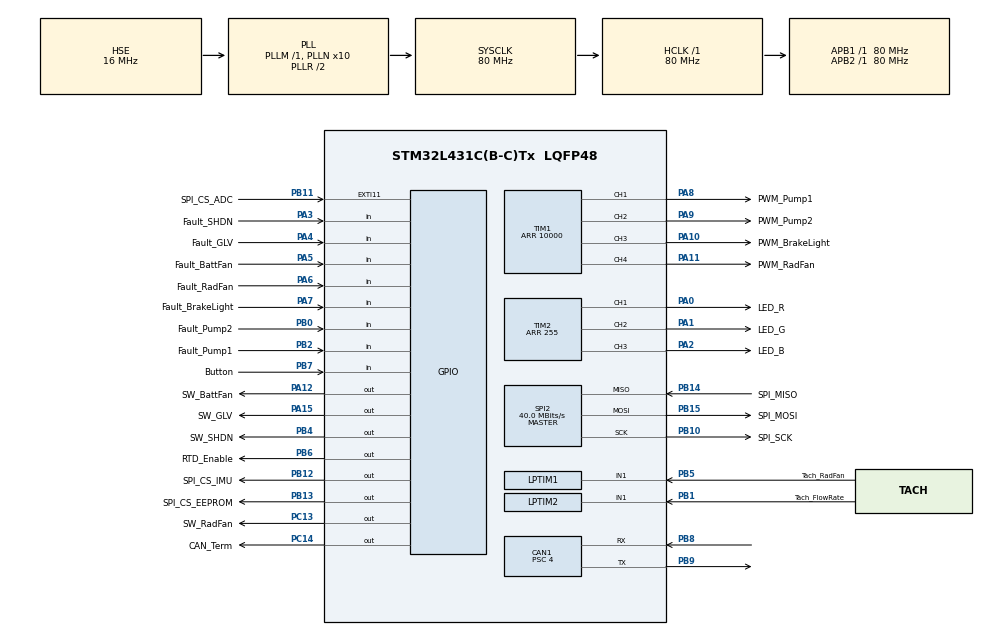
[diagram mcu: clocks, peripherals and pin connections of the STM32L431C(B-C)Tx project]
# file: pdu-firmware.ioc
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CAN1.BS1=CAN_BS1_16TQ
CAN1.BS2=CAN_BS2_3TQ
CAN1.CalculateBaudRate=1000000
CAN1.CalculateTimeBit=1000
CAN1.CalculateTimeQuantum=50.0
CAN1.Prescaler=4
Mcu.Family=STM32L4
Mcu.Name=STM32L431C(B-C)Tx
Mcu.Package=LQFP48
NVIC.PriorityGroup=NVIC_PRIORITYGROUP_4
PA0.GPIO_Label=LED_R
PA0.GPIO_ModeDefaultPP=GPIO_MODE_AF_OD
PA0.GPIO_Speed=GPIO_SPEED_FREQ_VERY_HIGH
PA0.Signal=S_TIM2_CH1
PA1.GPIO_Label=LED_G
PA1.GPIO_ModeDefaultPP=GPIO_MODE_AF_OD
PA1.GPIO_Speed=GPIO_SPEED_FREQ_VERY_HIGH
PA1.Signal=S_TIM2_CH2
PA10.GPIO_Label=PWM_BrakeLight
PA10.Signal=S_TIM1_CH3
PA11.GPIO_Label=PWM_RadFan
PA11.Signal=S_TIM1_CH4
PA12.GPIO_Label=SW_BattFan
PA12.Signal=GPIO_Output
PA13\ (JTMS-SWDIO).Mode=Trace_Asynchronous_SW
PA13\ (JTMS-SWDIO).Signal=SYS_JTMS-SWDIO
PA14\ (JTCK-SWCLK).Mode=Trace_Asynchronous_SW
PA14\ (JTCK-SWCLK).Signal=SYS_JTCK-SWCLK
PA15\ (JTDI).GPIO_Label=SW_GLV
PA15\ (JTDI).Signal=GPIO_Output
PA2.GPIO_Label=LED_B
PA2.GPIO_ModeDefaultPP=GPIO_MODE_AF_OD
PA2.GPIO_Speed=GPIO_SPEED_FREQ_VERY_HIGH
PA2.Signal=S_TIM2_CH3
PA3.GPIO_Label=Fault_SHDN
PA3.Signal=GPIO_Input
PA4.GPIO_Label=Fault_GLV
PA4.Signal=GPIO_Input
PA5.GPIO_Label=Fault_BattFan
PA5.Signal=GPIO_Input
PA6.GPIO_Label=Fault_RadFan
PA6.Signal=GPIO_Input
PA7.GPIO_Label=Fault_BrakeLight
PA7.Signal=GPIO_Input
PA8.GPIO_Label=PWM_Pump1
PA8.Signal=S_TIM1_CH1
PA9.GPIO_Label=PWM_Pump2
PA9.Signal=S_TIM1_CH2
PB0.GPIO_Label=Fault_Pump2
PB0.Signal=GPIO_Input
PB1.GPIO_Label=Tach_FlowRate
PB1.Mode=Counts_external_clock_standalone_1X_occur1
PB1.Signal=LPTIM2_IN1
PB10.GPIO_Label=SPI_SCK
PB10.Mode=Full_Duplex_Master
PB10.Signal=SPI2_SCK
PB11.GPIO_Label=SPI_CS_ADC
PB11.Signal=GPXTI11
PB12.GPIO_Label=SPI_CS_IMU
PB12.Signal=GPIO_Output
PB13.GPIO_Label=SPI_CS_EEPROM
PB13.Signal=GPIO_Output
PB14.GPIO_Label=SPI_MISO
PB14.Mode=Full_Duplex_Master
PB14.Signal=SPI2_MISO
PB15.GPIO_Label=SPI_MOSI
PB15.Mode=Full_Duplex_Master
PB15.Signal=SPI2_MOSI
PB2.GPIO_Label=Fault_Pump1
PB2.Signal=GPIO_Input
PB3\ (JTDO-TRACESWO).Mode=Trace_Asynchronous_SW
PB3\ (JTDO-TRACESWO).Signal=SYS_JTDO-SWO
PB4\ (NJTRST).GPIO_Label=SW_SHDN
PB4\ (NJTRST).Signal=GPIO_Output
PB5.GPIO_Label=Tach_RadFan
PB5.Mode=Counts_external_clock_standalone_1X_occur1
PB5.Signal=LPTIM1_IN1
PB6.GPIO_Label=RTD_Enable
PB6.Signal=GPIO_Output
PB7.GPIO_Label=Button
PB7.Signal=GPIO_Input
PB8.Mode=CAN_Activate
PB8.Signal=CAN1_RX
PB9.Mode=CAN_Activate
PB9.Signal=CAN1_TX
PC13.GPIO_Label=SW_RadFan
PC13.Signal=GPIO_Output
PC14-OSC32_IN\ (PC14).GPIO_Label=CAN_Term
PC14-OSC32_IN\ (PC14).Signal=GPIO_Output
PH0-OSC_IN\ (PH0).Mode=HSE-External-Oscillator
PH0-OSC_IN\ (PH0).Signal=RCC_OSC_IN
PH1-OSC_OUT\ (PH1).Mode=HSE-External-Oscillator
PH1-OSC_OUT\ (PH1).Signal=RCC_OSC_OUT
ProjectManager.HeapSize=0x200
ProjectManager.StackSize=0x400
ProjectManager.TargetToolchain=STM32CubeIDE
RCC.ADCFreq_Value=64000000
RCC.AHBFreq_Value=80000000
RCC.APB1Freq_Value=80000000
RCC.APB1TimFreq_Value=80000000
RCC.APB2Freq_Value=80000000
RCC.APB2TimFreq_Value=80000000
RCC.CortexFreq_Value=80000000
RCC.HCLKFreq_Value=80000000
RCC.HSE_VALUE=16000000
RCC.HSI48_VALUE=48000000
RCC.HSI_VALUE=16000000
RCC.LSE_VALUE=32768
RCC.MSI_VALUE=4000000
RCC.PLLN=10
RCC.PLLSourceVirtual=RCC_PLLSOURCE_HSE
RCC.SYSCLKFreq_VALUE=80000000
RCC.SYSCLKSource=RCC_SYSCLKSOURCE_PLLCLK
RCC.VCOOutputFreq_Value=160000000
SH.S_TIM1_CH1.0=TIM1_CH1,PWM Generation1 CH1
SH.S_TIM1_CH2.0=TIM1_CH2,PWM Generation2 CH2
SH.S_TIM1_CH3.0=TIM1_CH3,PWM Generation3 CH3
SH.S_TIM1_CH4.0=TIM1_CH4,PWM Generation4 CH4
SH.S_TIM2_CH1.0=TIM2_CH1,PWM Generation1 CH1
SH.S_TIM2_CH2.0=TIM2_CH2,PWM Generation2 CH2
SH.S_TIM2_CH3.0=TIM2_CH3,PWM Generation3 CH3
SPI2.CalculateBaudRate=40.0 MBits/s
SPI2.Direction=SPI_DIRECTION_2LINES
SPI2.Mode=SPI_MODE_MASTER
SPI2.VirtualType=VM_MASTER
TIM1.Channel-PWM\ Generation1\ CH1=TIM_CHANNEL_1
TIM1.Channel-PWM\ Generation2\ CH2=TIM_CHANNEL_2
TIM1.Channel-PWM\ Generation3\ CH3=TIM_CHANNEL_3
TIM1.Channel-PWM\ Generation4\ CH4=TIM_CHANNEL_4
TIM1.Period=10000
TIM2.AutoReloadPreload=TIM_AUTORELOAD_PRELOAD_ENABLE
TIM2.Channel-PWM\ Generation1\ CH1=TIM_CHANNEL_1
TIM2.Channel-PWM\ Generation2\ CH2=TIM_CHANNEL_2
TIM2.Channel-PWM\ Generation3\ CH3=TIM_CHANNEL_3
TIM2.OCPolarity_1=TIM_OCPOLARITY_LOW
TIM2.OCPolarity_2=TIM_OCPOLARITY_LOW
TIM2.OCPolarity_3=TIM_OCPOLARITY_LOW
TIM2.Period=255
VP_TIM1_VS_ClockSourceINT.Mode=Internal
VP_TIM2_VS_ClockSourceINT.Mode=Internal
board=custom

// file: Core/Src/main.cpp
/* USER CODE BEGIN Header */
/**
  ******************************************************************************
  * @file           : main.c
  * @brief          : Main program body
  ******************************************************************************
  * @attention
  *
  * Copyright (c) 2023 STMicroelectronics.
  * All rights reserved.
  *
  * This software is licensed under terms that can be found in the LICENSE file
  * in the root directory of this software component.
  * If no LICENSE file comes with this software, it is provided AS-IS.
  *
  ******************************************************************************
  */
/* USER CODE END Header */
#include "main.h"
#include "can.h"
#include "lptim.h"
#include "spi.h"
#include "tim.h"
#include "gpio.h"

/* USER CODE BEGIN Includes */
#include "clock.h"
#include "led.h"
#include "switches.h"
/* USER CODE END Includes */

void SystemClock_Config(void);

int main(void)
{

  /* MCU Configuration--------------------------------------------------------*/

  /* Reset of all peripherals, Initializes the Flash interface and the Systick. */
  HAL_Init();

  /* Configure the system clock */
  SystemClock_Config();

  /* Initialize all configured peripherals */
  MX_GPIO_Init();
  MX_CAN1_Init();
  MX_TIM2_Init();
  MX_SPI2_Init();
  MX_TIM1_Init();
  MX_LPTIM1_Init();
  MX_LPTIM2_Init();
  /* USER CODE BEGIN 2 */
  clock_init();
  led_init();
  switches_init();
  /* USER CODE END 2 */

  /* Infinite loop */
  while (1)
  {

    /* USER CODE BEGIN 3 */
    float deltaTime = clock_getDeltaTime();
    led_rainbow(deltaTime);

    int t = ((int)clock_getTime()) % 5;
    float pct = t / 4.0f;
    switches_setBrakeLight(pct*pct);
  }
  /* USER CODE END 3 */
}

void SystemClock_Config(void)
{
  RCC_OscInitTypeDef RCC_OscInitStruct = {0};
  RCC_ClkInitTypeDef RCC_ClkInitStruct = {0};

  /** Configure the main internal regulator output voltage
  */
  if (HAL_PWREx_ControlVoltageScaling(PWR_REGULATOR_VOLTAGE_SCALE1) != HAL_OK)
  {
    Error_Handler();
  }

  /** Initializes the RCC Oscillators according to the specified parameters
  * in the RCC_OscInitTypeDef structure.
  */
  RCC_OscInitStruct.OscillatorType = RCC_OSCILLATORTYPE_HSE;
  RCC_OscInitStruct.HSEState = RCC_HSE_ON;
  RCC_OscInitStruct.PLL.PLLState = RCC_PLL_ON;
  RCC_OscInitStruct.PLL.PLLSource = RCC_PLLSOURCE_HSE;
  RCC_OscInitStruct.PLL.PLLM = 1;
  RCC_OscInitStruct.PLL.PLLN = 10;
  RCC_OscInitStruct.PLL.PLLP = RCC_PLLP_DIV7;
  RCC_OscInitStruct.PLL.PLLQ = RCC_PLLQ_DIV2;
  RCC_OscInitStruct.PLL.PLLR = RCC_PLLR_DIV2;
  if (HAL_RCC_OscConfig(&RCC_OscInitStruct) != HAL_OK)
  {
    Error_Handler();
  }

  /** Initializes the CPU, AHB and APB buses clocks
  */
  RCC_ClkInitStruct.ClockType = RCC_CLOCKTYPE_HCLK|RCC_CLOCKTYPE_SYSCLK
                              |RCC_CLOCKTYPE_PCLK1|RCC_CLOCKTYPE_PCLK2;
  RCC_ClkInitStruct.SYSCLKSource = RCC_SYSCLKSOURCE_PLLCLK;
  RCC_ClkInitStruct.AHBCLKDivider = RCC_SYSCLK_DIV1;
  RCC_ClkInitStruct.APB1CLKDivider = RCC_HCLK_DIV1;
  RCC_ClkInitStruct.APB2CLKDivider = RCC_HCLK_DIV1;

  if (HAL_RCC_ClockConfig(&RCC_ClkInitStruct, FLASH_LATENCY_4) != HAL_OK)
  {
    Error_Handler();
  }
}

void Error_Handler(void)
{
  __disable_irq();
  while (1)
  {
  }
}
